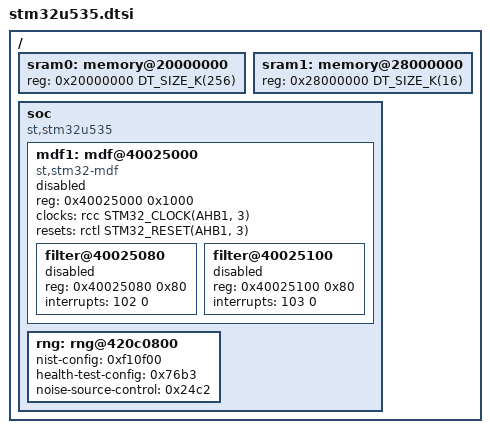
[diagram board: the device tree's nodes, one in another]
/*
 * Copyright (c) 2025 Harris Tomy
 *
 * SPDX-License-Identifier: Apache-2.0
 */

#include <st/u5/stm32u5_usb_fs.dtsi>

/ {
	sram0: memory@20000000 {
		/* SRAM1 + SRAM2 */
		reg = <0x20000000 DT_SIZE_K(256)>;
	};

	sram1: memory@28000000 {
		/* SRAM4, low-power background autonomous mode */
		reg = <0x28000000 DT_SIZE_K(16)>;
	};

	soc {
		compatible = "st,stm32u535", "st,stm32u5", "simple-bus";

		mdf1: mdf@40025000 {
			compatible = "st,stm32-mdf";
			reg = <0x40025000 0x1000>;
			clocks = <&rcc STM32_CLOCK(AHB1, 3)>;
			clock-names = "pclk";
			resets = <&rctl STM32_RESET(AHB1, 3)>;
			#address-cells = <1>;
			#size-cells = <1>;
			ranges;
			status = "disabled";

			filter@40025080 {
				reg = <0x40025080 0x80>;
				interrupts = <102 0>;
				status = "disabled";
			};

			filter@40025100 {
				reg = <0x40025100 0x80>;
				interrupts = <103 0>;
				status = "disabled";
			};
		};

		rng: rng@420c0800 {
			nist-config = <0xf10f00>;
			health-test-config = <0x76b3>;
			noise-source-control = <0x24c2>;
		};
	};
};
